# ESP32-S31 register map
Vendor: ESPRESSIF SYSTEMS (SHANGHAI) CO., LTD.; Series: ESP32 S-Series; File version: 1
CPU: RV32IMAFC r0p0, little endian, no MPU, FPU, 0 interrupt priority bits
Address unit: 32 bits
Registers are 32-bit, read-write, reset 0x0 unless marked. A register's access mark holds for its fields unless they carry their own. Offsets are from the block's base; [hi:lo] are bit positions; {n}, {i} and the like mark numbered series.

## UART0 — UART (Universal Asynchronous Receiver-Transmitter) Controller 0
Base 0x2038A000
Same registers: UART1 0x2038B000, UART2 0x2038C000, UART3 0x2038D000
0x00 FIFO ro — FIFO data register
  [7:0] RXFIFO_RD_BYTE — Represents the data UART 0 read from FIFO.\\ Measurement unit: byte.
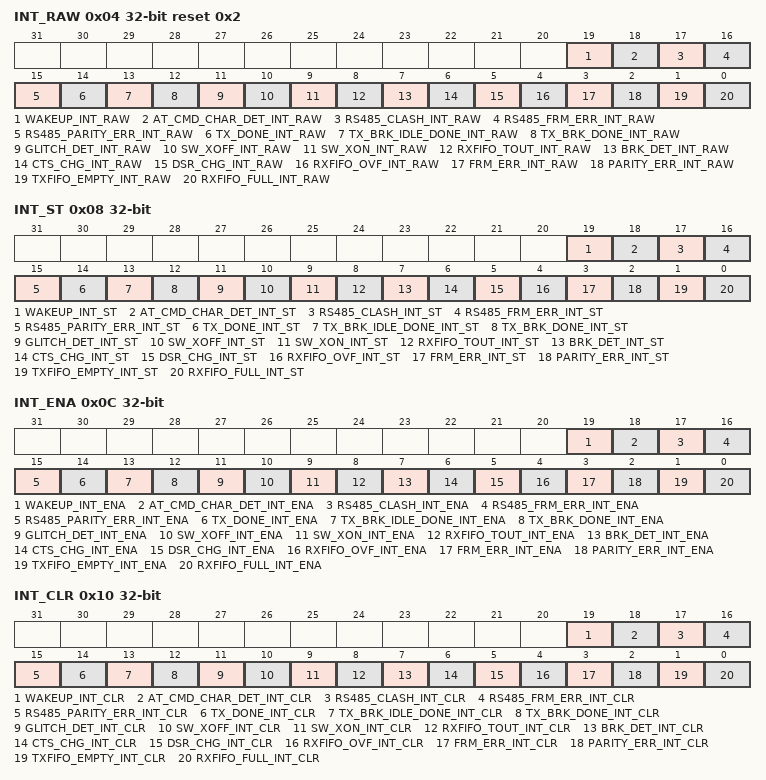
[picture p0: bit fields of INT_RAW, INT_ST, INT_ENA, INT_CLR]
0x04 INT_RAW reset 0x2 — Raw interrupt status
  [19] WAKEUP_INT_RAW — The raw interrupt status of UART_WAKEUP_INT.
  [18] AT_CMD_CHAR_DET_INT_RAW — The raw interrupt status of UART_AT_CMD_CHAR_DET_INT.
  [17] RS485_CLASH_INT_RAW — The raw interrupt status of UART_RS485_CLASH_INT.
  [16] RS485_FRM_ERR_INT_RAW — The raw interrupt status of UART_RS485_FRM_ERR_INT.
  [15] RS485_PARITY_ERR_INT_RAW — The raw interrupt status of UART_RS485_PARITY_ERR_INT.
  [14] TX_DONE_INT_RAW — The raw interrupt status of UART_TX_DONE_INT.
  [13] TX_BRK_IDLE_DONE_INT_RAW — The raw interrupt status of UART_TX_BRK_IDLE_DONE_INT.
  [12] TX_BRK_DONE_INT_RAW — The raw interrupt status of UART_TX_BRK_DONE_INT.
  [11] GLITCH_DET_INT_RAW — The raw interrupt status of UART_GLITCH_DET_INT.
  [10] SW_XOFF_INT_RAW — UART_SW_XOFF_INT.
  [9] SW_XON_INT_RAW — The raw interrupt status of UART_SW_XON_INT.
  [8] RXFIFO_TOUT_INT_RAW — The raw interrupt status of UART_RXFIFO_TOUT_INT.
  [7] BRK_DET_INT_RAW — The raw interrupt status of UART_BRK_DET_INT.
  [6] CTS_CHG_INT_RAW — The raw interrupt status of UART_CTS_CHG_INT.
  [5] DSR_CHG_INT_RAW — The raw interrupt status of UART_DSR_CHG_INT.
  [4] RXFIFO_OVF_INT_RAW — The raw interrupt status of UART_RXFIFO_OVF_INT.
  [3] FRM_ERR_INT_RAW — The raw interrupt status of UART_FRM_ERR_INT.
  [2] PARITY_ERR_INT_RAW — The raw interrupt status of UART_PARITY_ERR_INT.
  [1] TXFIFO_EMPTY_INT_RAW — The raw interrupt status of UART_TXFIFO_EMPTY_INT.
  [0] RXFIFO_FULL_INT_RAW — The raw interrupt status of UART_RXFIFO_FULL_INT.
0x08 INT_ST ro — Masked interrupt status
  [19] WAKEUP_INT_ST — The masked interrupt status of UART_WAKEUP_INT.
  [18] AT_CMD_CHAR_DET_INT_ST — The masked interrupt status of UART_AT_CMD_CHAR_DET_INT.
  [17] RS485_CLASH_INT_ST — The masked interrupt status of UART_RS485_CLASH_INT.
  [16] RS485_FRM_ERR_INT_ST — The masked interrupt status of UART_RS485_FRM_ERR_INT.
  [15] RS485_PARITY_ERR_INT_ST — The masked interrupt status of UART_RS485_PARITY_ERR_INT.
  [14] TX_DONE_INT_ST — The masked interrupt status of UART_TX_DONE_INT.
  [13] TX_BRK_IDLE_DONE_INT_ST — The masked interrupt status of UART_TX_BRK_IDLE_DONE_INT.
  [12] TX_BRK_DONE_INT_ST — The masked interrupt status of UART_TX_BRK_DONE_INT.
  [11] GLITCH_DET_INT_ST — The masked interrupt status of UART_GLITCH_DET_INT.
  [10] SW_XOFF_INT_ST — The masked interrupt status of UART_SW_XOFF_INT.
  [9] SW_XON_INT_ST — The masked interrupt status of UART_SW_XON_INT.
  [8] RXFIFO_TOUT_INT_ST — The masked interrupt status of UART_RXFIFO_TOUT_INT.
  [7] BRK_DET_INT_ST — The masked interrupt status of UART_BRK_DET_INT.
  [6] CTS_CHG_INT_ST — The masked interrupt status of UART_CTS_CHG_INT.
  [5] DSR_CHG_INT_ST — The masked interrupt status of UART_DSR_CHG_INT.
  [4] RXFIFO_OVF_INT_ST — The masked interrupt status of UART_RXFIFO_OVF_INT.
  [3] FRM_ERR_INT_ST — The masked interrupt status of UART_FRM_ERR_INT.
  [2] PARITY_ERR_INT_ST — The masked interrupt status of UART_PARITY_ERR_INT.
  [1] TXFIFO_EMPTY_INT_ST — The masked interrupt status of UART_TXFIFO_EMPTY_INT.
  [0] RXFIFO_FULL_INT_ST — The masked interrupt status of UART_RXFIFO_FULL_INT.
0x0C INT_ENA — Interrupt enable bits
  [19] WAKEUP_INT_ENA — Write 1 to enable UART_WAKEUP_INT.
  [18] AT_CMD_CHAR_DET_INT_ENA — Write 1 to enable UART_AT_CMD_CHAR_DET_INT.
  [17] RS485_CLASH_INT_ENA — Write 1 to enable UART_RS485_CLASH_INT.
  [16] RS485_FRM_ERR_INT_ENA — Write 1 to enable UART_RS485_FRM_ERR_INT.
  [15] RS485_PARITY_ERR_INT_ENA — Write 1 to enable UART_RS485_PARITY_ERR_INT.
  [14] TX_DONE_INT_ENA — Write 1 to enable UART_TX_DONE_INT.
  [13] TX_BRK_IDLE_DONE_INT_ENA — Write 1 to enable UART_TX_BRK_IDLE_DONE_INT.
  [12] TX_BRK_DONE_INT_ENA — Write 1 to enable UART_TX_BRK_DONE_INT.
  [11] GLITCH_DET_INT_ENA — Write 1 to enable UART_GLITCH_DET_INT.
  [10] SW_XOFF_INT_ENA — Write 1 to enable UART_SW_XOFF_INT.
  [9] SW_XON_INT_ENA — Write 1 to enable UART_SW_XON_INT.
  [8] RXFIFO_TOUT_INT_ENA — Write 1 to enable UART_RXFIFO_TOUT_INT.
  [7] BRK_DET_INT_ENA — Write 1 to enable UART_BRK_DET_INT.
  [6] CTS_CHG_INT_ENA — Write 1 to enable UART_CTS_CHG_INT.
  [5] DSR_CHG_INT_ENA — Write 1 to enable UART_DSR_CHG_INT.
  [4] RXFIFO_OVF_INT_ENA — Write 1 to enable UART_RXFIFO_OVF_INT.
  [3] FRM_ERR_INT_ENA — Write 1 to enable UART_FRM_ERR_INT.
  [2] PARITY_ERR_INT_ENA — Write 1 to enable UART_PARITY_ERR_INT.
  [1] TXFIFO_EMPTY_INT_ENA — Write 1 to enable UART_TXFIFO_EMPTY_INT.
  [0] RXFIFO_FULL_INT_ENA — Write 1 to enable UART_RXFIFO_FULL_INT.
0x10 INT_CLR wo — Interrupt clear bits
  [19] WAKEUP_INT_CLR — Write 1 to clear UART_WAKEUP_INT.
  [18] AT_CMD_CHAR_DET_INT_CLR — Write 1 to clear UART_AT_CMD_CHAR_DET_INT.
  [17] RS485_CLASH_INT_CLR — Write 1 to clear UART_RS485_CLASH_INT.
  [16] RS485_FRM_ERR_INT_CLR — Write 1 to clear UART_RS485_FRM_ERR_INT.
  [15] RS485_PARITY_ERR_INT_CLR — Write 1 to clear UART_RS485_PARITY_ERR_INT.
  [14] TX_DONE_INT_CLR — Write 1 to clear UART_TX_DONE_INT.
  [13] TX_BRK_IDLE_DONE_INT_CLR — Write 1 to clear UART_TX_BRK_IDLE_DONE_INT.
  [12] TX_BRK_DONE_INT_CLR — Write 1 to clear UART_TX_BRK_DONE_INT.
  [11] GLITCH_DET_INT_CLR — Write 1 to clear UART_GLITCH_DET_INT.
  [10] SW_XOFF_INT_CLR — Write 1 to clear UART_SW_XOFF_INT.
  [9] SW_XON_INT_CLR — Write 1 to clear UART_SW_XON_INT.
  [8] RXFIFO_TOUT_INT_CLR — Write 1 to clear UART_RXFIFO_TOUT_INT.
  [7] BRK_DET_INT_CLR — Write 1 to clear UART_BRK_DET_INT.
  [6] CTS_CHG_INT_CLR — Write 1 to clear UART_CTS_CHG_INT.
  [5] DSR_CHG_INT_CLR — Write 1 to clear UART_DSR_CHG_INT.
  [4] RXFIFO_OVF_INT_CLR — Write 1 to clear UART_RXFIFO_OVF_INT.
  [3] FRM_ERR_INT_CLR — Write 1 to clear UART_FRM_ERR_INT.
  [2] PARITY_ERR_INT_CLR — Write 1 to clear UART_PARITY_ERR_INT.
  [1] TXFIFO_EMPTY_INT_CLR — Write 1 to clear UART_TXFIFO_EMPTY_INT.
  [0] RXFIFO_FULL_INT_CLR — Write 1 to clear UART_RXFIFO_FULL_INT.
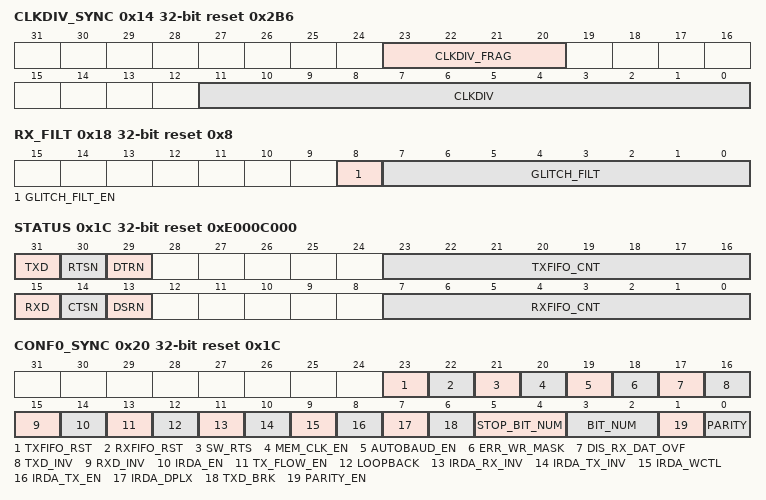
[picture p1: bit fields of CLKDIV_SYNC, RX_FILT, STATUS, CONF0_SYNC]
0x14 CLKDIV_SYNC reset 0x2B6 — Clock divider configuration
  [23:20] CLKDIV_FRAG — Configures the fractional part of the divisor for baud rate generation.
  [11:0] CLKDIV — Configures the integral part of the divisor for baud rate generation.
0x18 RX_FILT reset 0x8 — RX filter configuration
  [8] GLITCH_FILT_EN — Configures whether or not to enable RX signal filter.\\ 0: Disable\\ 1: Enable
  [7:0] GLITCH_FILT — Configures the width of a pulse to be filtered.\\Measurement unit: UART Core's clock cycle.\\Pulses whose width is lower than this value will be ignored.
0x1C STATUS ro reset 0xE000C000 — UART status register
  [31] TXD — Represents the level of the internal UART TXD signal.
  [30] RTSN — Represents the level of the internal UART RTS signal.
  [29] DTRN — Represents the level of the internal UART DTR signal.
  [23:16] TXFIFO_CNT — Represents the number of valid data bytes in RX FIFO.
  [15] RXD — Represents the level of the internal UART RXD signal.
  [14] CTSN — Represents the level of the internal UART CTS signal.
  [13] DSRN — Represents the level of the internal UART DSR signal.
  [7:0] RXFIFO_CNT — Represents the number of valid data bytes in RX FIFO.
0x20 CONF0_SYNC reset 0x1C — Configuration register 0
  [23] TXFIFO_RST — Configures whether or not to reset the UART TX FIFO.\\ 0: Not reset\\ 1: Reset\\
  [22] RXFIFO_RST — Configures whether or not to reset the UART RX FIFO.\\ 0: Not reset\\ 1: Reset\\
  [21] SW_RTS — Configures the RTS signal used in software flow control.\\ 0: The UART transmitter is allowed to send data.\\ 1: The UART transmitted is not allowed to send data.\\
  [20] MEM_CLK_EN — Configures whether or not to enable clock gating for UART memory.\\ 0: Disable\\ 1: Enable\\
  [19] AUTOBAUD_EN — Configures whether or not to enable baud rate detection.\\ 0: Disable\\ 1: Enable\\
  [18] ERR_WR_MASK — Configures whether or not to store the received data with errors into FIFO.\\ 0: Store\\ 1: Not store\\
  [17] DIS_RX_DAT_OVF — Configures whether or not to disable data overflow detection for the UART receiver.\\ 0: Enable\\ 1: Disable\\
  [16] TXD_INV — Configures whether or not to invert the level of UART TXD signal.\\ 0: Not invert\\ 1: Invert\\
  [15] RXD_INV — Configures whether or not to invert the level of UART RXD signal.\\ 0: Not invert\\ 1: Invert\\
  [14] IRDA_EN — Configures whether or not to enable IrDA protocol.\\ 0: Disable\\ 1: Enable\\
  [13] TX_FLOW_EN — Configures whether or not to enable flow control for the transmitter.\\ 0: Disable\\ 1: Enable\\
  [12] LOOPBACK — Configures whether or not to enable UART loopback test.\\ 0: Disable\\ 1: Enable\\
  [11] IRDA_RX_INV — Configures whether or not to invert the level of the IrDA receiver.\\ 0: Not invert\\ 1: Invert\\
  [10] IRDA_TX_INV — Configures whether or not to invert the level of the IrDA transmitter.\\ 0: Not invert\\ 1: Invert\\
  [9] IRDA_WCTL — Configures the 11th bit of the IrDA transmitter.\\ 0: This bit is 0.\\ 1: This bit is the same as the 10th bit.\\
  [8] IRDA_TX_EN — Configures whether or not to enable the IrDA transmitter.\\ 0: Disable\\ 1: Enable\\
  [7] IRDA_DPLX — Configures whether or not to enable IrDA loopback test.\\ 0: Disable\\ 1: Enable\\
  [6] TXD_BRK — Configures whether or not to send NULL characters when finishing data transmission.\\ 0: Not send\\ 1: Send\\
  [5:4] STOP_BIT_NUM — Configures the number of stop bits.\\ 0: Invalid. No effect\\ 1: 1 bits\\ 2: 1.5 bits\\ 3: 2 bits\\
  [3:2] BIT_NUM — Configures the number of data bits.\\ 0: 5 bits\\ 1: 6 bits\\ 2: 7 bits\\ 3: 8 bits\\
  [1] PARITY_EN — Configures whether or not to enable UART parity check.\\ 0: Disable\\ 1: Enable\\
  [0] PARITY — Configures the parity check mode.\\ 0: Even parity\\ 1: Odd parity\\
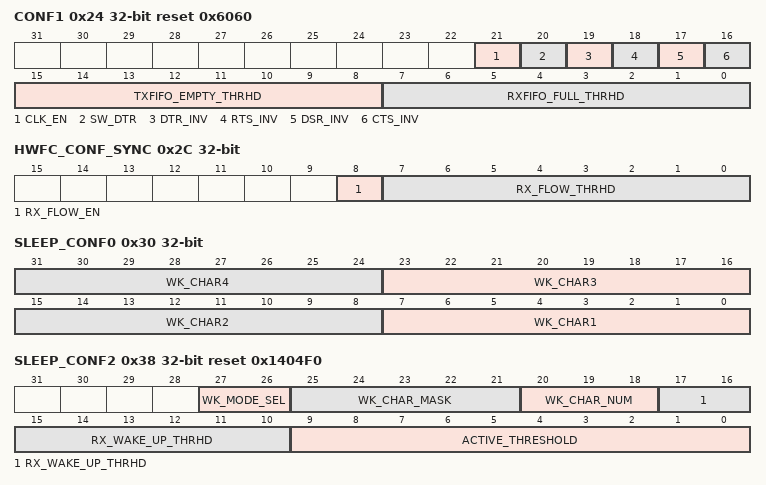
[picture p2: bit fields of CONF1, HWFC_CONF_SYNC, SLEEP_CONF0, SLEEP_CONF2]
0x24 CONF1 reset 0x6060 — Configuration register 1
  [21] CLK_EN — Configures clock gating.\\ 0: Support clock only when the application writes registers.\\ 1: Always force the clock on for registers.\\
  [20] SW_DTR — Configures the DTR signal used in software flow control.\\ 0: Data to be transmitted is not ready.\\ 1: Data to be transmitted is ready.\\
  [19] DTR_INV — Configures whether or not to invert the level of UART DTR signal.\\ 0: Not invert\\ 1: Invert\\
  [18] RTS_INV — Configures whether or not to invert the level of UART RTS signal.\\ 0: Not invert\\ 1: Invert\\
  [17] DSR_INV — Configures whether or not to invert the level of UART DSR signal.\\ 0: Not invert\\ 1: Invert\\
  [16] CTS_INV — Configures whether or not to invert the level of UART CTS signal.\\ 0: Not invert\\ 1: Invert\\
  [15:8] TXFIFO_EMPTY_THRHD — Configures the threshold for TX FIFO being empty.\\Measurement unit: byte.
  [7:0] RXFIFO_FULL_THRHD — Configures the threshold for RX FIFO being full.\\Measurement unit: byte.
0x2C HWFC_CONF_SYNC — Hardware flow control configuration
  [8] RX_FLOW_EN — Configures whether or not to enable the UART receiver.\\ 0: Disable\\ 1: Enable\\
  [7:0] RX_FLOW_THRHD — Configures the maximum number of data bytes that can be received during hardware flow control.\\Measurement unit: byte.
0x30 SLEEP_CONF0 — UART sleep configuration register 0
  [8n-1:8n-8] WK_CHAR{n} (n=1..4) — Configures wakeup character {n}.
0x34 SLEEP_CONF1 — UART sleep configuration register 1
  [7:0] WK_CHAR0 — Configures wakeup character 0.
0x38 SLEEP_CONF2 reset 0x1404F0 — UART sleep configuration register 2
  [27:26] WK_MODE_SEL — Configures which wakeup mode to select.\\ 0: Mode 0\\ 1: Mode 1\\ 2: Mode 2\\ 3: Mode 3\\
  [25:21] WK_CHAR_MASK — Configures whether or not to mask wakeup characters.\\ 0: Not mask\\ 1: Mask\\
  [20:18] WK_CHAR_NUM — Configures the number of wakeup characters.
  [17:10] RX_WAKE_UP_THRHD — Configures the number of received data bytes to wake up the chip in wakeup mode 1.
  [9:0] ACTIVE_THRESHOLD — Configures the number of RXD edge changes to wake up the chip in wakeup mode 0.
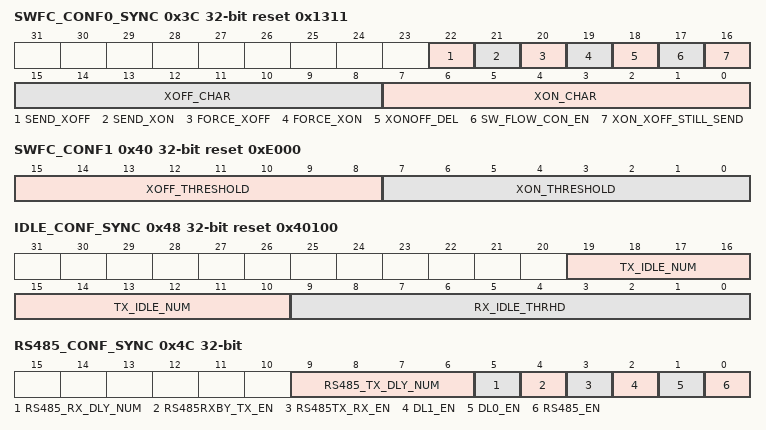
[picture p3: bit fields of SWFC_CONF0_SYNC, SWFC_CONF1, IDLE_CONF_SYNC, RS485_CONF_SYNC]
0x3C SWFC_CONF0_SYNC reset 0x1311 — Software flow control character configuration
  [22] SEND_XOFF — Configures whether or not to send XOFF characters.\\ 0: Not send\\ 1: Send\\
  [21] SEND_XON — Configures whether or not to send XON characters.\\ 0: Not send\\ 1: Send\\
  [20] FORCE_XOFF — Configures whether or not to stop the transmitter from sending data.\\ 0: Not stop\\ 1: Stop\\
  [19] FORCE_XON — Configures whether the transmitter continues to sending data.\\ 0: Not send\\ 1: Send\\
  [18] XONOFF_DEL — Configures whether or not to remove flow control characters from the received data.\\ 0: Not move\\ 1: Move\\
  [17] SW_FLOW_CON_EN — Configures whether or not to enable software flow control.\\ 0: Disable\\ 1: Enable\\
  [16] XON_XOFF_STILL_SEND — Configures whether the UART transmitter can send XON or XOFF characters when it is disabled.\\ 0: Cannot send\\ 1: Can send\\
  [15:8] XOFF_CHAR — Configures the XOFF character for flow control.
  [7:0] XON_CHAR — Configures the XON character for flow control.
0x40 SWFC_CONF1 reset 0xE000 — Software flow control character configuration
  [15:8] XOFF_THRESHOLD — Configures the threshold for data in RX FIFO to send XOFF characters in software flow control.\\Measurement unit: byte.
  [7:0] XON_THRESHOLD — Configures the threshold for data in RX FIFO to send XON characters in software flow control.\\Measurement unit: byte.
0x44 TXBRK_CONF_SYNC reset 0xA — TX break character configuration
  [7:0] TX_BRK_NUM — Configures the number of NULL characters to be sent after finishing data transmission.\\Valid only when UART_TXD_BRK is 1.
0x48 IDLE_CONF_SYNC reset 0x40100 — Frame end idle time configuration
  [19:10] TX_IDLE_NUM — Configures the interval between two data transfers.\\Measurement unit: bit time (the time to transmit 1 bit).
  [9:0] RX_IDLE_THRHD — Configures the threshold to generate a frame end signal when the receiver takes more time to receive one data byte data.\\Measurement unit: bit time (the time to transmit 1 bit).
0x4C RS485_CONF_SYNC — RS485 mode configuration
  [9:6] RS485_TX_DLY_NUM — Configures the delay of internal data signals in the transmitter.\\Measurement unit: bit time (the time to transmit 1 bit).
  [5] RS485_RX_DLY_NUM — Configures the delay of internal data signals in the receiver.\\Measurement unit: bit time (the time to transmit 1 bit)..
  [4] RS485RXBY_TX_EN — Configures whether to enable the RS485 transmitter for data transmission when the RS485 receiver is busy.\\ 0: Disable\\ 1: Enable\\
  [3] RS485TX_RX_EN — Configures whether or not to enable the receiver for data reception when the transmitter is transmitting data in RS485 mode.\\ 0: Disable\\ 1: Enable\\
  [2] DL1_EN — Configures whether or not to add a turnaround delay of 1 bit after the stop bit.\\ 0: Not add\\ 1: Add\\
  [1] DL0_EN — Configures whether or not to add a turnaround delay of 1 bit before the start bit.\\ 0: Not add\\ 1: Add\\
  [0] RS485_EN — Configures whether or not to enable RS485 mode.\\ 0: Disable\\ 1: Enable\\
0x50 AT_CMD_PRECNT_SYNC reset 0x901 — Pre-sequence timing configuration
  [15:0] PRE_IDLE_NUM — Configures the idle time before the receiver receives the first AT_CMD.\\Measurement unit: bit time (the time to transmit 1 bit).
0x54 AT_CMD_POSTCNT_SYNC reset 0x901 — Post-sequence timing configuration
  [15:0] POST_IDLE_NUM — Configures the interval between the last AT_CMD and subsequent data.\\Measurement unit: bit time (the time to transmit 1 bit).
0x58 AT_CMD_GAPTOUT_SYNC reset 0xB — Timeout configuration
  [15:0] RX_GAP_TOUT — Configures the interval between two AT_CMD characters.\\Measurement unit: bit time (the time to transmit 1 bit).
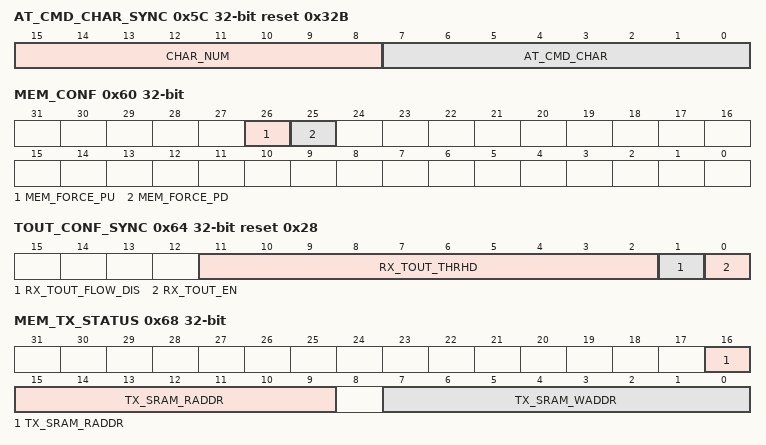
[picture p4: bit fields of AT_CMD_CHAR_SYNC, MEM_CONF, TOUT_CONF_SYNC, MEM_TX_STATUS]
0x5C AT_CMD_CHAR_SYNC reset 0x32B — AT escape sequence detection configuration
  [15:8] CHAR_NUM — Configures the number of continuous AT_CMD characters a receiver can receive.
  [7:0] AT_CMD_CHAR — Configures the AT_CMD character.
0x60 MEM_CONF — UART memory power configuration
  [26] MEM_FORCE_PU — Set this bit to force power up UART memory.
  [25] MEM_FORCE_PD — Set this bit to force power down UART memory.
0x64 TOUT_CONF_SYNC reset 0x28 — UART threshold and allocation configuration
  [11:2] RX_TOUT_THRHD — Configures the amount of time that the bus can remain idle before timeout.\\ Measurement unit: bit time (the time to transmit 1 bit).
  [1] RX_TOUT_FLOW_DIS — Set this bit to stop accumulating idle_cnt when hardware flow control works.
  [0] RX_TOUT_EN — Configures whether or not to enable UART receiver's timeout function.\\ 0: Disable\\ 1: Enable\\
0x68 MEM_TX_STATUS ro — TX FIFO write and read offset address
  [16:9] TX_SRAM_RADDR — Represents the offset address to read TX FIFO.
  [7:0] TX_SRAM_WADDR — Represents the offset address to write TX FIFO.
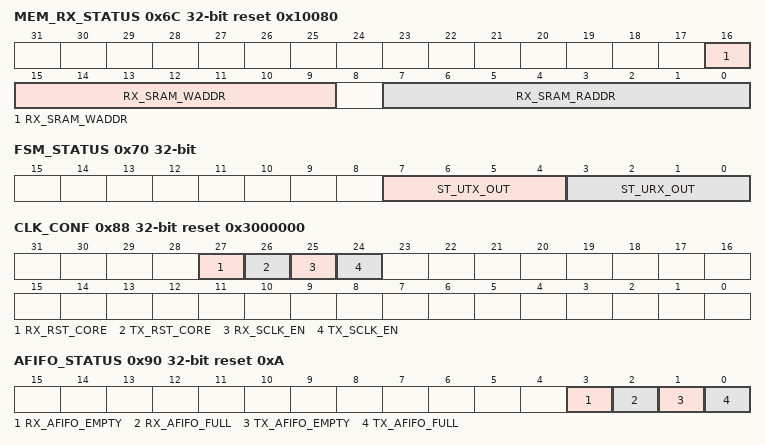
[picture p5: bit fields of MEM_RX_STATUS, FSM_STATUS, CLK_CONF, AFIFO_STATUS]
0x6C MEM_RX_STATUS ro reset 0x10080 — Rx FIFO write and read offset address
  [16:9] RX_SRAM_WADDR — Represents the offset address to write RX FIFO.
  [7:0] RX_SRAM_RADDR — Represents the offset address to read RX FIFO.
0x70 FSM_STATUS ro — UART transmit and receive status
  [7:4] ST_UTX_OUT — Represents the status of the transmitter.
  [3:0] ST_URX_OUT — Represents the status of the receiver.
0x74 POSPULSE ro reset 0xFFF — Autobaud high pulse register
  [11:0] POSEDGE_MIN_CNT — Represents the minimal input clock counter value between two positive edges. It is used for baud rate detection.
0x78 NEGPULSE ro reset 0xFFF — Autobaud low pulse register
  [11:0] NEGEDGE_MIN_CNT — Represents the minimal input clock counter value between two negative edges. It is used for baud rate detection.
0x7C LOWPULSE ro reset 0xFFF — Autobaud minimum low pulse duration register
  [11:0] MIN_CNT — Represents the minimum duration time of a low-level pulse. It is used for baud rate detection.\\Measurement unit: APB_CLK clock cycle.
0x80 HIGHPULSE ro reset 0xFFF — Autobaud minimum high pulse duration register
  [11:0] MIN_CNT — Represents the maximum duration time for a high-level pulse. It is used for baud rate detection.\\Measurement unit: APB_CLK clock cycle.
0x84 RXD_CNT ro — Autobaud edge change count register
  [9:0] RXD_EDGE_CNT — Represents the number of RXD edge changes. It is used for baud rate detection.
0x88 CLK_CONF reset 0x3000000 — UART core clock configuration
  [27] RX_RST_CORE — Write 1 and then write 0 to reset UART RX.
  [26] TX_RST_CORE — Write 1 and then write 0 to reset UART TX.
  [25] RX_SCLK_EN — Configures whether or not to enable UART RX clock.\\ 0: Disable\\ 1: Enable\\
  [24] TX_SCLK_EN — Configures whether or not to enable UART TX clock.\\ 0: Disable\\ 1: Enable\\
0x8C DATE reset 0x2312220 — UART version control register
  [31:0] DATE — Version control register.
0x90 AFIFO_STATUS ro reset 0xA — UART asynchronous FIFO status
  [3] RX_AFIFO_EMPTY — Represents whether or not the APB RX asynchronous FIFO is empty.\\ 0: Not empty\\ 1: Empty\\
  [2] RX_AFIFO_FULL — Represents whether or not the APB RX asynchronous FIFO is full.\\ 0: Not full\\ 1: Full\\
  [1] TX_AFIFO_EMPTY — Represents whether or not the APB TX asynchronous FIFO is empty.\\ 0: Not empty\\ 1: Empty\\
  [0] TX_AFIFO_FULL — Represents whether or not the APB TX asynchronous FIFO is full.\\ 0: Not full\\ 1: Full\\
0x98 REG_UPDATE — UART register configuration update
  [0] REG_UPDATE — Configures whether or not to synchronize registers.\\ 0: Not synchronize\\ 1: Synchronize\\
0x9C ID reset 0x500 — UART ID register
  [31:0] ID — Configures the UART ID.
